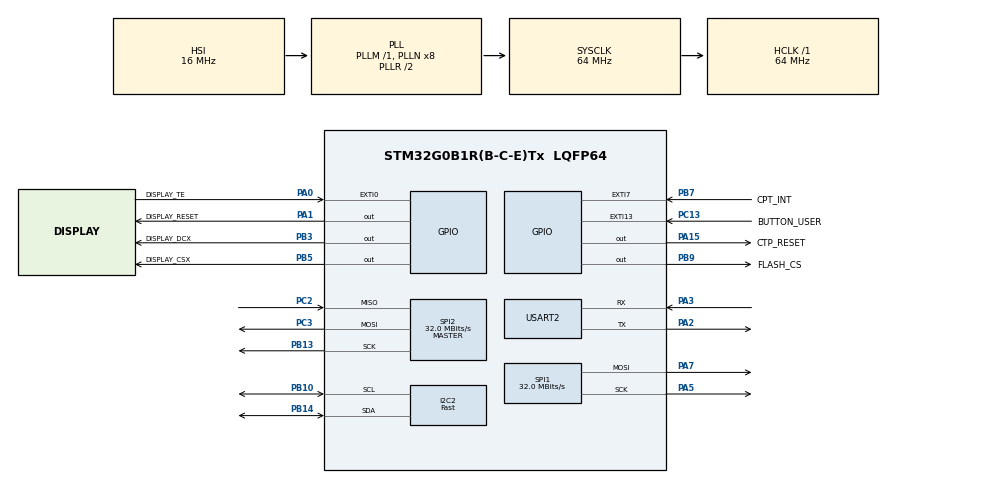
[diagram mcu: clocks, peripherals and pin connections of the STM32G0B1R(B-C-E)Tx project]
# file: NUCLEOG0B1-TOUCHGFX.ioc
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Dma.Request0=SPI1_TX
Dma.Request1=SPI2_RX
Dma.Request2=SPI2_TX
Dma.SPI1_TX.0.Direction=DMA_MEMORY_TO_PERIPH
Dma.SPI1_TX.0.EventEnable=DISABLE
Dma.SPI1_TX.0.Instance=DMA1_Channel1
Dma.SPI1_TX.0.MemDataAlignment=DMA_MDATAALIGN_HALFWORD
Dma.SPI1_TX.0.MemInc=DMA_MINC_ENABLE
Dma.SPI1_TX.0.Mode=DMA_NORMAL
Dma.SPI1_TX.0.PeriphDataAlignment=DMA_PDATAALIGN_HALFWORD
Dma.SPI1_TX.0.PeriphInc=DMA_PINC_DISABLE
Dma.SPI1_TX.0.Polarity=HAL_DMAMUX_REQ_GEN_RISING
Dma.SPI1_TX.0.Priority=DMA_PRIORITY_HIGH
Dma.SPI1_TX.0.RequestNumber=1
Dma.SPI1_TX.0.SignalID=NONE
Dma.SPI1_TX.0.SyncEnable=DISABLE
Dma.SPI1_TX.0.SyncPolarity=HAL_DMAMUX_SYNC_NO_EVENT
Dma.SPI1_TX.0.SyncRequestNumber=1
Dma.SPI1_TX.0.SyncSignalID=NONE
Dma.SPI2_RX.1.Direction=DMA_PERIPH_TO_MEMORY
Dma.SPI2_RX.1.EventEnable=DISABLE
Dma.SPI2_RX.1.Instance=DMA1_Channel2
Dma.SPI2_RX.1.MemDataAlignment=DMA_MDATAALIGN_BYTE
Dma.SPI2_RX.1.MemInc=DMA_MINC_ENABLE
Dma.SPI2_RX.1.Mode=DMA_NORMAL
Dma.SPI2_RX.1.PeriphDataAlignment=DMA_PDATAALIGN_BYTE
Dma.SPI2_RX.1.PeriphInc=DMA_PINC_DISABLE
Dma.SPI2_RX.1.Polarity=HAL_DMAMUX_REQ_GEN_RISING
Dma.SPI2_RX.1.Priority=DMA_PRIORITY_MEDIUM
Dma.SPI2_RX.1.RequestNumber=1
Dma.SPI2_RX.1.SignalID=NONE
Dma.SPI2_RX.1.SyncEnable=DISABLE
Dma.SPI2_RX.1.SyncPolarity=HAL_DMAMUX_SYNC_NO_EVENT
Dma.SPI2_RX.1.SyncRequestNumber=1
Dma.SPI2_RX.1.SyncSignalID=NONE
Dma.SPI2_TX.2.Direction=DMA_MEMORY_TO_PERIPH
Dma.SPI2_TX.2.EventEnable=DISABLE
Dma.SPI2_TX.2.Instance=DMA1_Channel3
Dma.SPI2_TX.2.MemDataAlignment=DMA_MDATAALIGN_BYTE
Dma.SPI2_TX.2.MemInc=DMA_MINC_ENABLE
Dma.SPI2_TX.2.Mode=DMA_NORMAL
Dma.SPI2_TX.2.PeriphDataAlignment=DMA_PDATAALIGN_BYTE
Dma.SPI2_TX.2.PeriphInc=DMA_PINC_DISABLE
Dma.SPI2_TX.2.Polarity=HAL_DMAMUX_REQ_GEN_RISING
Dma.SPI2_TX.2.Priority=DMA_PRIORITY_LOW
Dma.SPI2_TX.2.RequestNumber=1
Dma.SPI2_TX.2.SignalID=NONE
Dma.SPI2_TX.2.SyncEnable=DISABLE
Dma.SPI2_TX.2.SyncPolarity=HAL_DMAMUX_SYNC_NO_EVENT
Dma.SPI2_TX.2.SyncRequestNumber=1
Dma.SPI2_TX.2.SyncSignalID=NONE
I2C2.I2C_Speed_Mode=I2C_Fast
I2C2.Timing=0x00C12166
Mcu.Family=STM32G0
Mcu.Name=STM32G0B1R(B-C-E)Tx
Mcu.Package=LQFP64
NVIC.DMA1_Channel1_IRQn=true\:0\:0\:false\:false\:true\:false\:true\:true
NVIC.DMA1_Channel2_3_IRQn=true\:0\:0\:false\:false\:true\:false\:true\:true
NVIC.EXTI0_1_IRQn=true\:0\:0\:false\:false\:true\:true\:true\:true
NVIC.EXTI4_15_IRQn=true\:0\:0\:false\:false\:true\:true\:true\:true
NVIC.I2C2_3_IRQn=true\:0\:0\:false\:false\:true\:true\:true\:true
NVIC.SPI1_IRQn=true\:0\:0\:false\:false\:true\:true\:true\:true
NVIC.SPI2_3_IRQn=true\:0\:0\:false\:false\:true\:true\:true\:true
NVIC.TIM3_TIM4_IRQn=true\:0\:0\:false\:false\:true\:true\:true\:true
PA0.GPIO_Label=DISPLAY_TE
PA0.GPIO_ModeDefaultEXTI=GPIO_MODE_IT_FALLING
PA0.Signal=GPXTI0
PA1.GPIO_Label=DISPLAY_RESET
PA1.GPIO_PuPd=GPIO_PULLUP
PA1.GPIO_Speed=GPIO_SPEED_FREQ_HIGH
PA1.Signal=GPIO_Output
PA13.Mode=Serial_Wire
PA13.Signal=SYS_SWDIO
PA14-BOOT0.Mode=Serial_Wire
PA14-BOOT0.Signal=SYS_SWCLK
PA15.GPIO_Label=CTP_RESET
PA15.Signal=GPIO_Output
PA2.Mode=Asynchronous
PA2.Signal=USART2_TX
PA3.Mode=Asynchronous
PA3.Signal=USART2_RX
PA5.GPIO_PuPd=GPIO_PULLDOWN
PA5.GPIO_Speed=GPIO_SPEED_FREQ_HIGH
PA5.Mode=TX_Only_Simplex_Unidirect_Master
PA5.Signal=SPI1_SCK
PA7.GPIO_PuPd=GPIO_PULLDOWN
PA7.GPIO_Speed=GPIO_SPEED_FREQ_HIGH
PA7.Mode=TX_Only_Simplex_Unidirect_Master
PA7.Signal=SPI1_MOSI
PB10.GPIO_Pu=GPIO_PULLUP
PB10.GPIO_Speed=GPIO_SPEED_FREQ_HIGH
PB10.Mode=I2C
PB10.Signal=I2C2_SCL
PB13.GPIO_Mode=GPIO_MODE_AF_PP
PB13.GPIO_PuPd=GPIO_PULLDOWN
PB13.GPIO_Speed=GPIO_SPEED_FREQ_HIGH
PB13.Mode=Full_Duplex_Master
PB13.Signal=SPI2_SCK
PB14.GPIO_Pu=GPIO_PULLUP
PB14.GPIO_Speed=GPIO_SPEED_FREQ_HIGH
PB14.Mode=I2C
PB14.Signal=I2C2_SDA
PB3.GPIO_Label=DISPLAY_DCX
PB3.GPIO_PuPd=GPIO_PULLUP
PB3.GPIO_Speed=GPIO_SPEED_FREQ_VERY_HIGH
PB3.PinState=GPIO_PIN_SET
PB3.Signal=GPIO_Output
PB5.GPIO_Label=DISPLAY_CSX
PB5.GPIO_PuPd=GPIO_PULLUP
PB5.GPIO_Speed=GPIO_SPEED_FREQ_VERY_HIGH
PB5.PinState=GPIO_PIN_SET
PB5.Signal=GPIO_Output
PB7.GPIO_Label=CPT_INT
PB7.Signal=GPXTI7
PB9.GPIO_FM9=SYSCFG_FASTMODEPLUS_PB9
PB9.GPIO_Label=FLASH_CS
PB9.GPIO_Speed=GPIO_SPEED_FREQ_VERY_HIGH
PB9.PinState=GPIO_PIN_SET
PB9.Signal=GPIO_Output
PC13.GPIO_Label=BUTTON_USER
PC13.Signal=GPXTI13
PC14-OSC32_IN\ (PC14).Mode=LSE-External-Oscillator
PC14-OSC32_IN\ (PC14).Signal=RCC_OSC32_IN
PC15-OSC32_OUT\ (PC15).Mode=LSE-External-Oscillator
PC15-OSC32_OUT\ (PC15).Signal=RCC_OSC32_OUT
PC2.GPIO_Mode=GPIO_MODE_AF_PP
PC2.GPIO_PuPd=GPIO_PULLDOWN
PC2.GPIO_Speed=GPIO_SPEED_FREQ_HIGH
PC2.Mode=Full_Duplex_Master
PC2.Signal=SPI2_MISO
PC3.GPIO_Mode=GPIO_MODE_AF_PP
PC3.GPIO_PuPd=GPIO_PULLDOWN
PC3.GPIO_Speed=GPIO_SPEED_FREQ_HIGH
PC3.Mode=Full_Duplex_Master
PC3.Signal=SPI2_MOSI
PF0-OSC_IN\ (PF0).Mode=HSE-External-Clock-Source
PF0-OSC_IN\ (PF0).Signal=RCC_OSC_IN
ProjectManager.HeapSize=0x200
ProjectManager.StackSize=0x400
ProjectManager.TargetToolchain=STM32CubeIDE
RCC.ADCFreq_Value=64000000
RCC.AHBFreq_Value=64000000
RCC.CortexFreq_Value=64000000
RCC.EXTERNAL_CLOCK_VALUE=48000
RCC.HCLKFreq_Value=64000000
RCC.HSE_VALUE=8000000
RCC.HSI48_VALUE=48000000
RCC.HSI_VALUE=16000000
RCC.SYSCLKFreq_VALUE=64000000
RCC.SYSCLKSource=RCC_SYSCLKSOURCE_PLLCLK
RCC.USBFreq_Value=48000000
RCC.VCOOutputFreq_Value=128000000
SPI1.CalculateBaudRate=32.0 MBits/s
SPI1.DataSize=SPI_DATASIZE_8BIT
SPI1.Direction=SPI_DIRECTION_2LINES
SPI1.Mode=SPI_MODE_MASTER
SPI1.VirtualType=VM_MASTER
SPI2.CalculateBaudRate=32.0 MBits/s
SPI2.DataSize=SPI_DATASIZE_8BIT
SPI2.Direction=SPI_DIRECTION_2LINES
SPI2.Mode=SPI_MODE_MASTER
SPI2.VirtualType=VM_MASTER
STMicroelectronics.X-CUBE-TOUCHGFX.4.25.0.ApplicationCcGraphicsJjApplication=TouchGFXOoGenerator
STMicroelectronics.X-CUBE-TOUCHGFX.4.25.0.tgfx_buffering_strategy=Partial
STMicroelectronics.X-CUBE-TOUCHGFX.4.25.0.tgfx_custom_height=320
STMicroelectronics.X-CUBE-TOUCHGFX.4.25.0.tgfx_custom_width=240
STMicroelectronics.X-CUBE-TOUCHGFX.4.25.0.tgfx_datareader=Enabled
STMicroelectronics.X-CUBE-TOUCHGFX.4.25.0.tgfx_partialfb_transmit_strategy=Enabled
STMicroelectronics.X-CUBE-TOUCHGFX.4.25.0_IsPackSelfContextualization=true
TIM2.Period=65535
TIM2.Prescaler=2520
TIM2.TIM_MasterOutputTrigger=TIM_TRGO_ENABLE
TIM3.Period=10000
TIM3.Prescaler=6400
USART2.VirtualMode-Asynchronous=VM_ASYNC
VP_CRC_VS_CRC.Mode=CRC_Activate
VP_STMicroelectronics.X-CUBE-TOUCHGFX_VS_GraphicsJjApplication_4.25.0.Mode=GraphicsJjApplication
VP_SYS_VS_DBSignals.Mode=DisableDeadBatterySignals
VP_TIM2_VS_ClockSourceINT.Mode=Internal
VP_TIM3_VS_ClockSourceINT.Mode=Internal
board=custom

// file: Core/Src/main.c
/* USER CODE BEGIN Header */
/**
  ******************************************************************************
  * @file           : main.c
  * @brief          : Main program body
  ******************************************************************************
  * @attention
  *
  * Copyright (c) 2024 STMicroelectronics.
  * All rights reserved.
  *
  * This software is licensed under terms that can be found in the LICENSE file
  * in the root directory of this software component.
  * If no LICENSE file comes with this software, it is provided AS-IS.
  *
  ******************************************************************************
  */
/* USER CODE END Header */
#include "main.h"
#include "app_touchgfx.h"

/* USER CODE BEGIN Includes */
#include "touch_driver.h"
/* USER CODE END Includes */

CRC_HandleTypeDef hcrc;

I2C_HandleTypeDef hi2c2;

SPI_HandleTypeDef hspi1;
SPI_HandleTypeDef hspi2;
DMA_HandleTypeDef hdma_spi1_tx;
DMA_HandleTypeDef hdma_spi2_rx;
DMA_HandleTypeDef hdma_spi2_tx;

TIM_HandleTypeDef htim2;
TIM_HandleTypeDef htim3;

UART_HandleTypeDef huart2;

/* USER CODE BEGIN PV */
sitronix_handle_t handle = {
		.device_address = SITRONIX_TOUCH_ADDRESS ,
		.i2c_handle = &hi2c2
};
__IO uint8_t User_ButtonState = 0;
/* USER CODE END PV */

void SystemClock_Config(void);
static void MX_GPIO_Init(void);
static void MX_DMA_Init(void);
static void MX_I2C2_Init(void);
static void MX_SPI1_Init(void);
static void MX_SPI2_Init(void);
static void MX_TIM2_Init(void);
static void MX_USART2_UART_Init(void);
static void MX_CRC_Init(void);
static void MX_TIM3_Init(void);

int main(void)
{

  /* MCU Configuration--------------------------------------------------------*/

  /* Reset of all peripherals, Initializes the Flash interface and the Systick. */
  HAL_Init();

  /* Configure the system clock */
  SystemClock_Config();

  /* Initialize all configured peripherals */
  MX_GPIO_Init();
  MX_DMA_Init();
  MX_I2C2_Init();
  MX_SPI1_Init();
  MX_SPI2_Init();
  MX_TIM2_Init();
  MX_USART2_UART_Init();
  MX_CRC_Init();
  MX_TIM3_Init();
	sitronix_hardware_reset();
	HAL_Delay(300);
	sitronix_version_get(&handle);
	sitronix_status_get(&handle);
	sitronix_close_multitouch(&handle);
  MX_TouchGFX_Init();

  /* Infinite loop */
  while (1)
  {

  MX_TouchGFX_Process();
  }
}

void SystemClock_Config(void)
{
  RCC_OscInitTypeDef RCC_OscInitStruct = {0};
  RCC_ClkInitTypeDef RCC_ClkInitStruct = {0};

  /** Configure the main internal regulator output voltage
  */
  HAL_PWREx_ControlVoltageScaling(PWR_REGULATOR_VOLTAGE_SCALE1);

  /** Initializes the RCC Oscillators according to the specified parameters
  * in the RCC_OscInitTypeDef structure.
  */
  RCC_OscInitStruct.OscillatorType = RCC_OSCILLATORTYPE_HSI;
  RCC_OscInitStruct.HSIState = RCC_HSI_ON;
  RCC_OscInitStruct.HSIDiv = RCC_HSI_DIV1;
  RCC_OscInitStruct.HSICalibrationValue = RCC_HSICALIBRATION_DEFAULT;
  RCC_OscInitStruct.PLL.PLLState = RCC_PLL_ON;
  RCC_OscInitStruct.PLL.PLLSource = RCC_PLLSOURCE_HSI;
  RCC_OscInitStruct.PLL.PLLM = RCC_PLLM_DIV1;
  RCC_OscInitStruct.PLL.PLLN = 8;
  RCC_OscInitStruct.PLL.PLLP = RCC_PLLP_DIV2;
  RCC_OscInitStruct.PLL.PLLQ = RCC_PLLQ_DIV2;
  RCC_OscInitStruct.PLL.PLLR = RCC_PLLR_DIV2;
  if (HAL_RCC_OscConfig(&RCC_OscInitStruct) != HAL_OK)
  {
    Error_Handler();
  }

  /** Initializes the CPU, AHB and APB buses clocks
  */
  RCC_ClkInitStruct.ClockType = RCC_CLOCKTYPE_HCLK|RCC_CLOCKTYPE_SYSCLK
                              |RCC_CLOCKTYPE_PCLK1;
  RCC_ClkInitStruct.SYSCLKSource = RCC_SYSCLKSOURCE_PLLCLK;
  RCC_ClkInitStruct.AHBCLKDivider = RCC_SYSCLK_DIV1;
  RCC_ClkInitStruct.APB1CLKDivider = RCC_HCLK_DIV1;

  if (HAL_RCC_ClockConfig(&RCC_ClkInitStruct, FLASH_LATENCY_2) != HAL_OK)
  {
    Error_Handler();
  }
}

static void MX_CRC_Init(void)
{

  hcrc.Instance = CRC;
  hcrc.Init.DefaultPolynomialUse = DEFAULT_POLYNOMIAL_ENABLE;
  hcrc.Init.DefaultInitValueUse = DEFAULT_INIT_VALUE_ENABLE;
  hcrc.Init.InputDataInversionMode = CRC_INPUTDATA_INVERSION_NONE;
  hcrc.Init.OutputDataInversionMode = CRC_OUTPUTDATA_INVERSION_DISABLE;
  hcrc.InputDataFormat = CRC_INPUTDATA_FORMAT_BYTES;
  if (HAL_CRC_Init(&hcrc) != HAL_OK)
  {
    Error_Handler();
  }

}

static void MX_I2C2_Init(void)
{

  hi2c2.Instance = I2C2;
  hi2c2.Init.Timing = 0x00C12166;
  hi2c2.Init.OwnAddress1 = 0;
  hi2c2.Init.AddressingMode = I2C_ADDRESSINGMODE_7BIT;
  hi2c2.Init.DualAddressMode = I2C_DUALADDRESS_DISABLE;
  hi2c2.Init.OwnAddress2 = 0;
  hi2c2.Init.OwnAddress2Masks = I2C_OA2_NOMASK;
  hi2c2.Init.GeneralCallMode = I2C_GENERALCALL_DISABLE;
  hi2c2.Init.NoStretchMode = I2C_NOSTRETCH_DISABLE;
  if (HAL_I2C_Init(&hi2c2) != HAL_OK)
  {
    Error_Handler();
  }

  /** Configure Analogue filter
  */
  if (HAL_I2CEx_ConfigAnalogFilter(&hi2c2, I2C_ANALOGFILTER_ENABLE) != HAL_OK)
  {
    Error_Handler();
  }

  /** Configure Digital filter
  */
  if (HAL_I2CEx_ConfigDigitalFilter(&hi2c2, 0) != HAL_OK)
  {
    Error_Handler();
  }

}

static void MX_SPI1_Init(void)
{

  /* SPI1 parameter configuration*/
  hspi1.Instance = SPI1;
  hspi1.Init.Mode = SPI_MODE_MASTER;
  hspi1.Init.Direction = SPI_DIRECTION_2LINES;
  hspi1.Init.DataSize = SPI_DATASIZE_8BIT;
  hspi1.Init.CLKPolarity = SPI_POLARITY_LOW;
  hspi1.Init.CLKPhase = SPI_PHASE_1EDGE;
  hspi1.Init.NSS = SPI_NSS_SOFT;
  hspi1.Init.BaudRatePrescaler = SPI_BAUDRATEPRESCALER_2;
  hspi1.Init.FirstBit = SPI_FIRSTBIT_MSB;
  hspi1.Init.TIMode = SPI_TIMODE_DISABLE;
  hspi1.Init.CRCCalculation = SPI_CRCCALCULATION_DISABLE;
  hspi1.Init.CRCPolynomial = 7;
  hspi1.Init.CRCLength = SPI_CRC_LENGTH_DATASIZE;
  hspi1.Init.NSSPMode = SPI_NSS_PULSE_ENABLE;
  if (HAL_SPI_Init(&hspi1) != HAL_OK)
  {
    Error_Handler();
  }

}

static void MX_SPI2_Init(void)
{

  /* SPI2 parameter configuration*/
  hspi2.Instance = SPI2;
  hspi2.Init.Mode = SPI_MODE_MASTER;
  hspi2.Init.Direction = SPI_DIRECTION_2LINES;
  hspi2.Init.DataSize = SPI_DATASIZE_8BIT;
  hspi2.Init.CLKPolarity = SPI_POLARITY_LOW;
  hspi2.Init.CLKPhase = SPI_PHASE_1EDGE;
  hspi2.Init.NSS = SPI_NSS_SOFT;
  hspi2.Init.BaudRatePrescaler = SPI_BAUDRATEPRESCALER_2;
  hspi2.Init.FirstBit = SPI_FIRSTBIT_MSB;
  hspi2.Init.TIMode = SPI_TIMODE_DISABLE;
  hspi2.Init.CRCCalculation = SPI_CRCCALCULATION_DISABLE;
  hspi2.Init.CRCPolynomial = 7;
  hspi2.Init.CRCLength = SPI_CRC_LENGTH_DATASIZE;
  hspi2.Init.NSSPMode = SPI_NSS_PULSE_ENABLE;
  if (HAL_SPI_Init(&hspi2) != HAL_OK)
  {
    Error_Handler();
  }

}

static void MX_TIM2_Init(void)
{

  TIM_ClockConfigTypeDef sClockSourceConfig = {0};
  TIM_MasterConfigTypeDef sMasterConfig = {0};

  htim2.Instance = TIM2;
  htim2.Init.Prescaler = 2520;
  htim2.Init.CounterMode = TIM_COUNTERMODE_UP;
  htim2.Init.Period = 65535;
  htim2.Init.ClockDivision = TIM_CLOCKDIVISION_DIV1;
  htim2.Init.AutoReloadPreload = TIM_AUTORELOAD_PRELOAD_DISABLE;
  if (HAL_TIM_Base_Init(&htim2) != HAL_OK)
  {
    Error_Handler();
  }
  sClockSourceConfig.ClockSource = TIM_CLOCKSOURCE_INTERNAL;
  if (HAL_TIM_ConfigClockSource(&htim2, &sClockSourceConfig) != HAL_OK)
  {
    Error_Handler();
  }
  sMasterConfig.MasterOutputTrigger = TIM_TRGO_ENABLE;
  sMasterConfig.MasterSlaveMode = TIM_MASTERSLAVEMODE_DISABLE;
  if (HAL_TIMEx_MasterConfigSynchronization(&htim2, &sMasterConfig) != HAL_OK)
  {
    Error_Handler();
  }

}

static void MX_TIM3_Init(void)
{

  TIM_ClockConfigTypeDef sClockSourceConfig = {0};
  TIM_MasterConfigTypeDef sMasterConfig = {0};

  htim3.Instance = TIM3;
  htim3.Init.Prescaler = 6400;
  htim3.Init.CounterMode = TIM_COUNTERMODE_UP;
  htim3.Init.Period = 10000;
  htim3.Init.ClockDivision = TIM_CLOCKDIVISION_DIV1;
  htim3.Init.AutoReloadPreload = TIM_AUTORELOAD_PRELOAD_DISABLE;
  if (HAL_TIM_Base_Init(&htim3) != HAL_OK)
  {
    Error_Handler();
  }
  sClockSourceConfig.ClockSource = TIM_CLOCKSOURCE_INTERNAL;
  if (HAL_TIM_ConfigClockSource(&htim3, &sClockSourceConfig) != HAL_OK)
  {
    Error_Handler();
  }
  sMasterConfig.MasterOutputTrigger = TIM_TRGO_RESET;
  sMasterConfig.MasterSlaveMode = TIM_MASTERSLAVEMODE_DISABLE;
  if (HAL_TIMEx_MasterConfigSynchronization(&htim3, &sMasterConfig) != HAL_OK)
  {
    Error_Handler();
  }

}

static void MX_USART2_UART_Init(void)
{

  huart2.Instance = USART2;
  huart2.Init.BaudRate = 115200;
  huart2.Init.WordLength = UART_WORDLENGTH_8B;
  huart2.Init.StopBits = UART_STOPBITS_1;
  huart2.Init.Parity = UART_PARITY_NONE;
  huart2.Init.Mode = UART_MODE_TX_RX;
  huart2.Init.HwFlowCtl = UART_HWCONTROL_NONE;
  huart2.Init.OverSampling = UART_OVERSAMPLING_16;
  huart2.Init.OneBitSampling = UART_ONE_BIT_SAMPLE_DISABLE;
  huart2.Init.ClockPrescaler = UART_PRESCALER_DIV1;
  huart2.AdvancedInit.AdvFeatureInit = UART_ADVFEATURE_NO_INIT;
  if (HAL_UART_Init(&huart2) != HAL_OK)
  {
    Error_Handler();
  }
  if (HAL_UARTEx_SetTxFifoThreshold(&huart2, UART_TXFIFO_THRESHOLD_1_8) != HAL_OK)
  {
    Error_Handler();
  }
  if (HAL_UARTEx_SetRxFifoThreshold(&huart2, UART_RXFIFO_THRESHOLD_1_8) != HAL_OK)
  {
    Error_Handler();
  }
  if (HAL_UARTEx_DisableFifoMode(&huart2) != HAL_OK)
  {
    Error_Handler();
  }

}

static void MX_DMA_Init(void)
{

  /* DMA controller clock enable */
  __HAL_RCC_DMA1_CLK_ENABLE();

  /* DMA interrupt init */
  /* DMA1_Channel1_IRQn interrupt configuration */
  HAL_NVIC_SetPriority(DMA1_Channel1_IRQn, 0, 0);
  HAL_NVIC_EnableIRQ(DMA1_Channel1_IRQn);
  /* DMA1_Channel2_3_IRQn interrupt configuration */
  HAL_NVIC_SetPriority(DMA1_Channel2_3_IRQn, 0, 0);
  HAL_NVIC_EnableIRQ(DMA1_Channel2_3_IRQn);

}

static void MX_GPIO_Init(void)
{
  GPIO_InitTypeDef GPIO_InitStruct = {0};

  /* GPIO Ports Clock Enable */
  __HAL_RCC_GPIOC_CLK_ENABLE();
  __HAL_RCC_GPIOF_CLK_ENABLE();
  __HAL_RCC_GPIOA_CLK_ENABLE();
  __HAL_RCC_GPIOB_CLK_ENABLE();

  /*Configure GPIO pin Output Level */
  HAL_GPIO_WritePin(GPIOA, DISPLAY_RESET_Pin|CTP_RESET_Pin, GPIO_PIN_RESET);

  /*Configure GPIO pin Output Level */
  HAL_GPIO_WritePin(GPIOB, DISPLAY_DCX_Pin|DISPLAY_CSX_Pin|FLASH_CS_Pin, GPIO_PIN_SET);

  /*Configure GPIO pin : BUTTON_USER_Pin */
  GPIO_InitStruct.Pin = BUTTON_USER_Pin;
  GPIO_InitStruct.Mode = GPIO_MODE_IT_RISING;
  GPIO_InitStruct.Pull = GPIO_NOPULL;
  HAL_GPIO_Init(BUTTON_USER_GPIO_Port, &GPIO_InitStruct);

  /*Configure GPIO pin : DISPLAY_TE_Pin */
  GPIO_InitStruct.Pin = DISPLAY_TE_Pin;
  GPIO_InitStruct.Mode = GPIO_MODE_IT_FALLING;
  GPIO_InitStruct.Pull = GPIO_NOPULL;
  HAL_GPIO_Init(DISPLAY_TE_GPIO_Port, &GPIO_InitStruct);

  /*Configure GPIO pin : DISPLAY_RESET_Pin */
  GPIO_InitStruct.Pin = DISPLAY_RESET_Pin;
  GPIO_InitStruct.Mode = GPIO_MODE_OUTPUT_PP;
  GPIO_InitStruct.Pull = GPIO_PULLUP;
  GPIO_InitStruct.Speed = GPIO_SPEED_FREQ_HIGH;
  HAL_GPIO_Init(DISPLAY_RESET_GPIO_Port, &GPIO_InitStruct);

  /*Configure GPIO pin : CTP_RESET_Pin */
  GPIO_InitStruct.Pin = CTP_RESET_Pin;
  GPIO_InitStruct.Mode = GPIO_MODE_OUTPUT_PP;
  GPIO_InitStruct.Pull = GPIO_NOPULL;
  GPIO_InitStruct.Speed = GPIO_SPEED_FREQ_LOW;
  HAL_GPIO_Init(CTP_RESET_GPIO_Port, &GPIO_InitStruct);

  /*Configure GPIO pins : DISPLAY_DCX_Pin DISPLAY_CSX_Pin */
  GPIO_InitStruct.Pin = DISPLAY_DCX_Pin|DISPLAY_CSX_Pin;
  GPIO_InitStruct.Mode = GPIO_MODE_OUTPUT_PP;
  GPIO_InitStruct.Pull = GPIO_PULLUP;
  GPIO_InitStruct.Speed = GPIO_SPEED_FREQ_VERY_HIGH;
  HAL_GPIO_Init(GPIOB, &GPIO_InitStruct);

  /*Configure GPIO pin : CPT_INT_Pin */
  GPIO_InitStruct.Pin = CPT_INT_Pin;
  GPIO_InitStruct.Mode = GPIO_MODE_IT_RISING;
  GPIO_InitStruct.Pull = GPIO_NOPULL;
  HAL_GPIO_Init(CPT_INT_GPIO_Port, &GPIO_InitStruct);

  /*Configure GPIO pin : FLASH_CS_Pin */
  GPIO_InitStruct.Pin = FLASH_CS_Pin;
  GPIO_InitStruct.Mode = GPIO_MODE_OUTPUT_PP;
  GPIO_InitStruct.Pull = GPIO_NOPULL;
  GPIO_InitStruct.Speed = GPIO_SPEED_FREQ_VERY_HIGH;
  HAL_GPIO_Init(FLASH_CS_GPIO_Port, &GPIO_InitStruct);

  /**/
  __HAL_SYSCFG_FASTMODEPLUS_ENABLE(SYSCFG_FASTMODEPLUS_PB9);

  /* EXTI interrupt init*/
  HAL_NVIC_SetPriority(EXTI0_1_IRQn, 0, 0);
  HAL_NVIC_EnableIRQ(EXTI0_1_IRQn);

  HAL_NVIC_SetPriority(EXTI4_15_IRQn, 0, 0);
  HAL_NVIC_EnableIRQ(EXTI4_15_IRQn);

}

void Error_Handler(void)
{
  __disable_irq();
  while (1)
  {
  }
}
